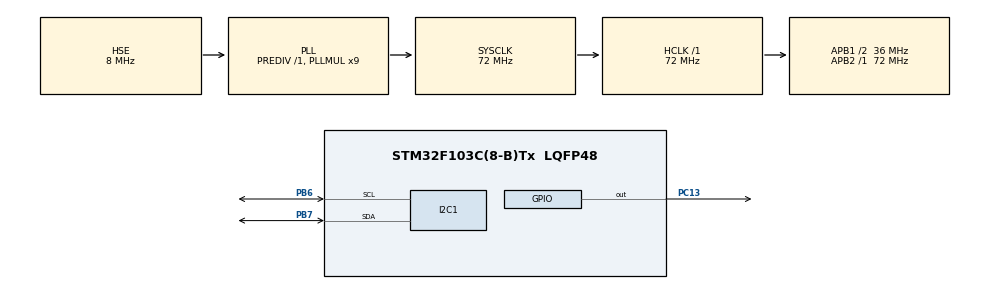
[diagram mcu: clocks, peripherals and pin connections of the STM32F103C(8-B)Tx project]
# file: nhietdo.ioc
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Mcu.Family=STM32F1
Mcu.Name=STM32F103C(8-B)Tx
Mcu.Package=LQFP48
NVIC.PriorityGroup=NVIC_PRIORITYGROUP_4
PA13.Mode=Serial_Wire
PA13.Signal=SYS_JTMS-SWDIO
PA14.Mode=Serial_Wire
PA14.Signal=SYS_JTCK-SWCLK
PB6.Mode=I2C
PB6.Signal=I2C1_SCL
PB7.Mode=I2C
PB7.Signal=I2C1_SDA
PC13-TAMPER-RTC.Signal=GPIO_Output
PD0-OSC_IN.Mode=HSE-External-Oscillator
PD0-OSC_IN.Signal=RCC_OSC_IN
PD1-OSC_OUT.Mode=HSE-External-Oscillator
PD1-OSC_OUT.Signal=RCC_OSC_OUT
ProjectManager.HeapSize=0x200
ProjectManager.StackSize=0x400
ProjectManager.TargetToolchain=MDK-ARM V5.27
RCC.AHBFreq_Value=72000000
RCC.APB1CLKDivider=RCC_HCLK_DIV2
RCC.APB1Freq_Value=36000000
RCC.APB1TimFreq_Value=72000000
RCC.APB2Freq_Value=72000000
RCC.APB2TimFreq_Value=72000000
RCC.HCLKFreq_Value=72000000
RCC.PLLMUL=RCC_PLL_MUL9
RCC.PLLSourceVirtual=RCC_PLLSOURCE_HSE
RCC.SYSCLKFreq_VALUE=72000000
RCC.SYSCLKSource=RCC_SYSCLKSOURCE_PLLCLK
RCC.USBFreq_Value=72000000
TIM1.Prescaler=71
VP_TIM1_VS_ClockSourceINT.Mode=Internal
board=custom

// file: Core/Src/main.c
/* USER CODE BEGIN Header */
/**
  ******************************************************************************
  * @file           : main.c
  * @brief          : Main program body
  ******************************************************************************
  * @attention
  *
  * <h2><center>&copy; Copyright (c) 2021 STMicroelectronics.
  * All rights reserved.</center></h2>
  *
  * This software component is licensed by ST under BSD 3-Clause license,
  * the "License"; You may not use this file except in compliance with the
  * License. You may obtain a copy of the License at:
  *                        opensource.org/licenses/BSD-3-Clause
  *
  ******************************************************************************
  */
/* USER CODE END Header */
#include "main.h"

/* USER CODE BEGIN Includes */
//#include "i2c-lcd.h"
#include "stdio.h"

/* USER CODE END Includes */

/* USER CODE BEGIN PD */
#define DHT22_PORT GPIOA
#define DHT22_PIN GPIO_PIN_1

/* USER CODE END PD */

I2C_HandleTypeDef hi2c1;

TIM_HandleTypeDef htim1;

/* USER CODE BEGIN PV */

void delay_us(uint16_t us)
{
  htim1.Instance = TIM1;
  htim1.Init.CounterMode = TIM_COUNTERMODE_UP;
  htim1.Init.Period = us;
	HAL_TIM_Base_Start(&htim1);
	__HAL_TIM_SetCounter(&htim1,0);
	while(__HAL_TIM_GetCounter(&htim1)<us)
	{

	}
}

uint8_t Rh_byte1, Rh_byte2, Temp_byte1, Temp_byte2;
uint16_t SUM, RH, TEMP;

float Temperature = 0;
float Humidity = 0;
uint8_t Presence = 0;

void Set_Pin_Output (GPIO_TypeDef *GPIOx, uint16_t GPIO_Pin)
{
	GPIO_InitTypeDef GPIO_InitStruct = {0};
	GPIO_InitStruct.Pin = GPIO_Pin;
	GPIO_InitStruct.Mode = GPIO_MODE_OUTPUT_PP;
	GPIO_InitStruct.Speed = GPIO_SPEED_FREQ_LOW;
	HAL_GPIO_Init(GPIOx, &GPIO_InitStruct);
}

void Set_Pin_Input (GPIO_TypeDef *GPIOx, uint16_t GPIO_Pin)
{
	GPIO_InitTypeDef GPIO_InitStruct = {0};
	GPIO_InitStruct.Pin = GPIO_Pin;
	GPIO_InitStruct.Mode = GPIO_MODE_INPUT;
	GPIO_InitStruct.Pull = GPIO_PULLUP;
	HAL_GPIO_Init(GPIOx, &GPIO_InitStruct);
}
#define DHT22_PORT GPIOA
#define DHT22_PIN GPIO_PIN_1

void DHT22_Start (void)
{
	Set_Pin_Output(DHT22_PORT, DHT22_PIN); // set the pin as output
	HAL_GPIO_WritePin (DHT22_PORT, DHT22_PIN, 0);   // pull the pin low
	delay_us(1200);   // wait for > 1ms

	HAL_GPIO_WritePin (DHT22_PORT, DHT22_PIN, 1);   // pull the pin high
	delay_us (20);   // wait for 30us

	Set_Pin_Input(DHT22_PORT, DHT22_PIN);   // set as input
}

uint8_t DHT22_Check_Response (void)
{
	Set_Pin_Input(DHT22_PORT, DHT22_PIN);   // set as input
	uint8_t Response = 0;
	delay_us (40);  // wait for 40us
	if (!(HAL_GPIO_ReadPin (DHT22_PORT, DHT22_PIN))) // if the pin is low
	{
		delay_us (80);   // wait for 80us

		if ((HAL_GPIO_ReadPin (DHT22_PORT, DHT22_PIN))) Response = 1;  // if the pin is high, response is ok
		else Response = -1;
	}

	while ((HAL_GPIO_ReadPin (DHT22_PORT, DHT22_PIN)));   // wait for the pin to go low
	return Response;
}

uint8_t DHT22_Read (void)
{
	uint8_t i,j;
	for (j=0;j<8;j++)
	{
		while (!(HAL_GPIO_ReadPin (DHT22_PORT, DHT22_PIN)));   // wait for the pin to go high
		delay_us (40);   // wait for 40 us

		if (!(HAL_GPIO_ReadPin (DHT22_PORT, DHT22_PIN)))   // if the pin is low
		{
			i&= ~(1<<(7-j));   // write 0
		}
		else i|= (1<<(7-j));  // if the pin is high, write 1
		while ((HAL_GPIO_ReadPin (DHT22_PORT, DHT22_PIN)));  // wait for the pin to go low
	}

	return i;
}
void get_data()
{
   DHT22_Start();
	  Presence = DHT22_Check_Response();
	  Rh_byte1 = DHT22_Read ();
      Rh_byte2 = DHT22_Read ();
	  Temp_byte1 = DHT22_Read ();
	  Temp_byte2 = DHT22_Read ();
	  SUM = DHT22_Read();

	  TEMP = ((Temp_byte1<<8)|Temp_byte2);
	  RH = ((Rh_byte1<<8)|Rh_byte2);

	  Temperature = (float) (TEMP/10.0);
	  Humidity = (float) (RH/10.0);
		HAL_GPIO_TogglePin(GPIOC,GPIO_PIN_13);
		HAL_Delay(1000);
}

/* USER CODE END PV */

void SystemClock_Config(void);
static void MX_GPIO_Init(void);
static void MX_I2C1_Init(void);
static void MX_TIM1_Init(void);

int main(void)
{

  /* MCU Configuration--------------------------------------------------------*/

  /* Reset of all peripherals, Initializes the Flash interface and the Systick. */
  HAL_Init();

  /* Configure the system clock */
  SystemClock_Config();

  /* USER CODE BEGIN SysInit */
  HAL_TIM_Base_Start(&htim1);
  /* USER CODE END SysInit */

  /* Initialize all configured peripherals */
  MX_GPIO_Init();
  MX_I2C1_Init();
  MX_TIM1_Init();

  /* Infinite loop */
  while (1)
  {

    /* USER CODE BEGIN 3 */

		get_data();
  }
  /* USER CODE END 3 */
}

void SystemClock_Config(void)
{
  RCC_OscInitTypeDef RCC_OscInitStruct = {0};
  RCC_ClkInitTypeDef RCC_ClkInitStruct = {0};

  /** Initializes the RCC Oscillators according to the specified parameters
  * in the RCC_OscInitTypeDef structure.
  */
  RCC_OscInitStruct.OscillatorType = RCC_OSCILLATORTYPE_HSE;
  RCC_OscInitStruct.HSEState = RCC_HSE_ON;
  RCC_OscInitStruct.HSEPredivValue = RCC_HSE_PREDIV_DIV1;
  RCC_OscInitStruct.HSIState = RCC_HSI_ON;
  RCC_OscInitStruct.PLL.PLLState = RCC_PLL_ON;
  RCC_OscInitStruct.PLL.PLLSource = RCC_PLLSOURCE_HSE;
  RCC_OscInitStruct.PLL.PLLMUL = RCC_PLL_MUL9;
  if (HAL_RCC_OscConfig(&RCC_OscInitStruct) != HAL_OK)
  {
    Error_Handler();
  }
  /** Initializes the CPU, AHB and APB buses clocks
  */
  RCC_ClkInitStruct.ClockType = RCC_CLOCKTYPE_HCLK|RCC_CLOCKTYPE_SYSCLK
                              |RCC_CLOCKTYPE_PCLK1|RCC_CLOCKTYPE_PCLK2;
  RCC_ClkInitStruct.SYSCLKSource = RCC_SYSCLKSOURCE_PLLCLK;
  RCC_ClkInitStruct.AHBCLKDivider = RCC_SYSCLK_DIV1;
  RCC_ClkInitStruct.APB1CLKDivider = RCC_HCLK_DIV2;
  RCC_ClkInitStruct.APB2CLKDivider = RCC_HCLK_DIV1;

  if (HAL_RCC_ClockConfig(&RCC_ClkInitStruct, FLASH_LATENCY_2) != HAL_OK)
  {
    Error_Handler();
  }
}

static void MX_I2C1_Init(void)
{

  hi2c1.Instance = I2C1;
  hi2c1.Init.ClockSpeed = 100000;
  hi2c1.Init.DutyCycle = I2C_DUTYCYCLE_2;
  hi2c1.Init.OwnAddress1 = 0;
  hi2c1.Init.AddressingMode = I2C_ADDRESSINGMODE_7BIT;
  hi2c1.Init.DualAddressMode = I2C_DUALADDRESS_DISABLE;
  hi2c1.Init.OwnAddress2 = 0;
  hi2c1.Init.GeneralCallMode = I2C_GENERALCALL_DISABLE;
  hi2c1.Init.NoStretchMode = I2C_NOSTRETCH_DISABLE;
  if (HAL_I2C_Init(&hi2c1) != HAL_OK)
  {
    Error_Handler();
  }

}

static void MX_TIM1_Init(void)
{

  TIM_ClockConfigTypeDef sClockSourceConfig = {0};
  TIM_MasterConfigTypeDef sMasterConfig = {0};

  htim1.Instance = TIM1;
  htim1.Init.Prescaler = 71;
  htim1.Init.CounterMode = TIM_COUNTERMODE_UP;
  htim1.Init.Period = 65535;
  htim1.Init.ClockDivision = TIM_CLOCKDIVISION_DIV1;
  htim1.Init.RepetitionCounter = 0;
  htim1.Init.AutoReloadPreload = TIM_AUTORELOAD_PRELOAD_DISABLE;
  if (HAL_TIM_Base_Init(&htim1) != HAL_OK)
  {
    Error_Handler();
  }
  sClockSourceConfig.ClockSource = TIM_CLOCKSOURCE_INTERNAL;
  if (HAL_TIM_ConfigClockSource(&htim1, &sClockSourceConfig) != HAL_OK)
  {
    Error_Handler();
  }
  sMasterConfig.MasterOutputTrigger = TIM_TRGO_RESET;
  sMasterConfig.MasterSlaveMode = TIM_MASTERSLAVEMODE_DISABLE;
  if (HAL_TIMEx_MasterConfigSynchronization(&htim1, &sMasterConfig) != HAL_OK)
  {
    Error_Handler();
  }

}

static void MX_GPIO_Init(void)
{
  GPIO_InitTypeDef GPIO_InitStruct = {0};

  /* GPIO Ports Clock Enable */
  __HAL_RCC_GPIOC_CLK_ENABLE();
  __HAL_RCC_GPIOD_CLK_ENABLE();
  __HAL_RCC_GPIOA_CLK_ENABLE();
  __HAL_RCC_GPIOB_CLK_ENABLE();

  /*Configure GPIO pin Output Level */
  HAL_GPIO_WritePin(GPIOC, GPIO_PIN_13, GPIO_PIN_RESET);

  /*Configure GPIO pin : PC13 */
  GPIO_InitStruct.Pin = GPIO_PIN_13;
  GPIO_InitStruct.Mode = GPIO_MODE_OUTPUT_PP;
  GPIO_InitStruct.Pull = GPIO_NOPULL;
  GPIO_InitStruct.Speed = GPIO_SPEED_FREQ_LOW;
  HAL_GPIO_Init(GPIOC, &GPIO_InitStruct);

}

void Error_Handler(void)
{
  __disable_irq();
  while (1)
  {
  }
}

/************************ (C) COPYRIGHT STMicroelectronics *****END OF FILE****/
